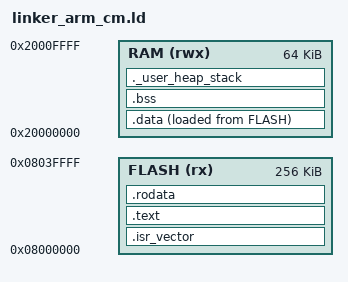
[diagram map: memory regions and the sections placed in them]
/* Linker script for ARM Cortex-M Bare-Metal Target */
ENTRY(Reset_Handler)

MEMORY
{
    FLASH (rx) : ORIGIN = 0x08000000, LENGTH = 256K
    RAM  (rwx) : ORIGIN = 0x20000000, LENGTH = 64K
}

_estack = ORIGIN(RAM) + LENGTH(RAM);

SECTIONS
{
    .isr_vector :
    {
        . = ALIGN(4);
        KEEP(*(.isr_vector))
        . = ALIGN(4);
    } > FLASH

    .text :
    {
        . = ALIGN(4);
        *(.text)
        *(.text*)
        *(.glue_7)
        *(.glue_7t)
        *(.eh_frame)
        KEEP (*(.init))
        KEEP (*(.fini))
        . = ALIGN(4);
        _etext = .;
    } > FLASH

    .rodata :
    {
        . = ALIGN(4);
        *(.rodata)
        *(.rodata*)
        . = ALIGN(4);
    } > FLASH

    _sidata = LOADADDR(.data);

    .data :
    {
        . = ALIGN(4);
        _sdata = .;
        *(.data)
        *(.data*)
        . = ALIGN(4);
        _edata = .;
    } > RAM AT > FLASH

    .bss :
    {
        . = ALIGN(4);
        _sbss = .;
        *(.bss)
        *(.bss*)
        *(COMMON)
        . = ALIGN(4);
        _ebss = .;
    } > RAM

    ._user_heap_stack :
    {
        . = ALIGN(8);
        PROVIDE ( end = . );
        PROVIDE ( _end = . );
        . = . + 0x1000; /* 4K heap */
        . = . + 0x1000; /* 4K stack */
        . = ALIGN(8);
    } > RAM
}
